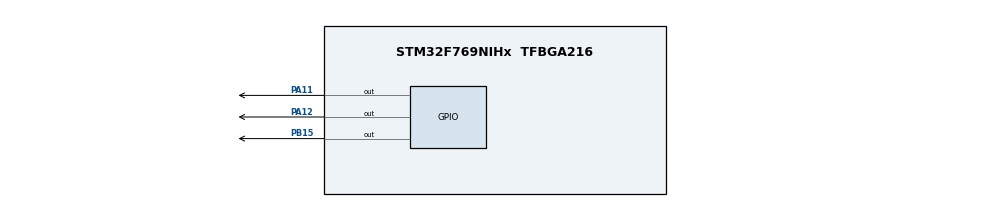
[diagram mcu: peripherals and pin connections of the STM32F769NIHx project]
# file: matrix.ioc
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Mcu.Family=STM32F7
Mcu.Name=STM32F769NIHx
Mcu.Package=TFBGA216
NVIC.PriorityGroup=NVIC_PRIORITYGROUP_4
PA11.Signal=GPIO_Output
PA12.Signal=GPIO_Output
PB15.Signal=GPIO_Output
ProjectManager.HeapSize=0x200
ProjectManager.StackSize=0x400
ProjectManager.TargetToolchain=STM32CubeIDE
RCC.HSE_VALUE=25000000
RCC.HSI_VALUE=16000000
RCC.LSE_VALUE=32768
RCC.USBFreq_Value=96000000
RCC.VCOOutputFreq_Value=192000000
board=custom

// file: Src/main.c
/* USER CODE BEGIN Header */
/**
  ******************************************************************************
  * @file           : main.c
  * @brief          : Main program body
  ******************************************************************************
  * @attention
  *
  * <h2><center>&copy; Copyright (c) 2019 STMicroelectronics.
  * All rights reserved.</center></h2>
  *
  * This software component is licensed by ST under BSD 3-Clause license,
  * the "License"; You may not use this file except in compliance with the
  * License. You may obtain a copy of the License at:
  *                        opensource.org/licenses/BSD-3-Clause
  *
  ******************************************************************************
  */
/* USER CODE END Header */

#include "main.h"

/* USER CODE BEGIN PTD */
uint8_t disp1ay[38][8]={
{0x3C,0x42,0x42,0x42,0x42,0x42,0x42,0x3C},//0
{0x10,0x30,0x50,0x10,0x10,0x10,0x10,0x7c},//1
{0x7E,0x2,0x2,0x7E,0x40,0x40,0x40,0x7E},//2
{0x3E,0x2,0x2,0x3E,0x2,0x2,0x3E,0x0},//3
{0x8,0x18,0x28,0x48,0xFE,0x8,0x8,0x8},//4
{0x3C,0x20,0x20,0x3C,0x4,0x4,0x3C,0x0},//5
{0x3C,0x20,0x20,0x3C,0x24,0x24,0x3C,0x0},//6
{0x3E,0x22,0x4,0x8,0x8,0x8,0x8,0x8},//7
{0x0,0x3E,0x22,0x22,0x3E,0x22,0x22,0x3E},//8
{0x3E,0x22,0x22,0x3E,0x2,0x2,0x2,0x3E},//9
{0x18,0x24,0x42,0x42,0x7E,0x42,0x42,0x42},//A
{0x3C,0x22,0x22,0x3c,0x22,0x22,0x3C,0x0},//B
{0x3C,0x40,0x40,0x40,0x40,0x40,0x40,0x3C},//C
{0x7C,0x22,0x22,0x22,0x22,0x22,0x22,0x7C},//D
{0x7C,0x40,0x40,0x7C,0x40,0x40,0x40,0x7C},//E
{0x7C,0x40,0x40,0x7C,0x40,0x40,0x40,0x40},//F
{0x3C,0x40,0x40,0x40,0x4c,0x44,0x44,0x3C},//G
{0x44,0x44,0x44,0x7C,0x44,0x44,0x44,0x44},//H
{0x7C,0x10,0x10,0x10,0x10,0x10,0x10,0x7C},//I
{0x3C,0x8,0x8,0x8,0x8,0x8,0x48,0x30},//J
{0x0,0x24,0x28,0x30,0x20,0x30,0x28,0x24},//K
{0x40,0x40,0x40,0x40,0x40,0x40,0x40,0x7C},//L
{0x81,0xC3,0xA5,0x99,0x81,0x81,0x81,0x81},//M
{0x0,0x42,0x62,0x52,0x4A,0x46,0x42,0x0},//N
{0x3C,0x42,0x42,0x42,0x42,0x42,0x42,0x3C},//O
{0x3C,0x22,0x22,0x22,0x3C,0x20,0x20,0x20},//P
{0x1C,0x22,0x22,0x22,0x22,0x26,0x22,0x1D},//Q
{0x3C,0x22,0x22,0x22,0x3C,0x24,0x22,0x21},//R
{0x0,0x1E,0x20,0x20,0x3E,0x2,0x2,0x3C},//S
{0x0,0x3E,0x8,0x8,0x8,0x8,0x8,0x8},//T
{0x42,0x42,0x42,0x42,0x42,0x42,0x22,0x1C},//U
{0x42,0x42,0x42,0x42,0x42,0x42,0x24,0x18},//V
{0x0,0x49,0x49,0x49,0x49,0x2A,0x1C,0x0},//W
{0x0,0x41,0x22,0x14,0x8,0x14,0x22,0x41},//X
{0x41,0x22,0x14,0x8,0x8,0x8,0x8,0x8},//Y
{0x0,0x7F,0x2,0x4,0x8,0x10,0x20,0x7F},//Z
{0x1C,0x1C,0x7F,0x5D,0x5D,0x14,0x14,0x14},//standing man
{0x38,0x38,0x7E,0x7A,0xBA,0x44,0x42,0x41},//walking man
};
/* USER CODE END PTD */

void SystemClock_Config(void);
static void MX_GPIO_Init(void);

/* USER CODE BEGIN 0 */
void write_byte(uint8_t byte)
{
	    for(int i=0;i<8;i++)
          {
	    	 HAL_GPIO_WritePin(GPIOA, GPIO_PIN_12, 0);  // Pull the CLK LOW
	    	 HAL_GPIO_WritePin(GPIOB, GPIO_PIN_15, byte&0x80);// Write one BIT data MSB first
             byte = byte<<1;  // shift the data to the left
             HAL_GPIO_WritePin(GPIOA, GPIO_PIN_12, 1);  // Pull the CLK HIGH
           }
}

void write_max (uint8_t address, uint8_t data)
{
	HAL_GPIO_WritePin(GPIOA, GPIO_PIN_11, 0);   // Pull the CS pin LOW
    write_byte(address);   //  write address
    write_byte(data);  //  write data
    HAL_GPIO_WritePin(GPIOA, GPIO_PIN_11, 1);  // pull the CS HIGH
}

void max_init(void)
{
 write_max(0x09, 0x00);       //  no decoding
 write_max(0x0a, 0x03);       //  brightness intensity
 write_max(0x0b, 0x07);       //  scan limit = 8 LEDs
 write_max(0x0c, 0x01);       //  power down =0，normal mode = 1
 write_max(0x0f, 0x00);       //  no test display
}
/* USER CODE END 0 */

int main(void)
{

  /* MCU Configuration--------------------------------------------------------*/

  /* Reset of all peripherals, Initializes the Flash interface and the Systick. */
  HAL_Init();

  /* Configure the system clock */
  SystemClock_Config();

  /* Initialize all configured peripherals */
  MX_GPIO_Init();

  /* Infinite loop */
  /* USER CODE BEGIN WHILE */
  max_init();
  while (1)
  {
    /* USER CODE END WHILE */
	  for(int i=1;i<9;i++)
	  {
		  write_max (i,disp1ay[36][i-1]);
	  }
	  HAL_Delay (300);
	  for(int i=1;i<9;i++)
	  {
		  write_max (i,disp1ay[37][i-1]);
	  }
	  HAL_Delay (300);
  }
}

void SystemClock_Config(void)
{
  RCC_OscInitTypeDef RCC_OscInitStruct = {0};
  RCC_ClkInitTypeDef RCC_ClkInitStruct = {0};

  /** Configure the main internal regulator output voltage
  */
  __HAL_RCC_PWR_CLK_ENABLE();
  __HAL_PWR_VOLTAGESCALING_CONFIG(PWR_REGULATOR_VOLTAGE_SCALE3);
  /** Initializes the CPU, AHB and APB busses clocks
  */
  RCC_OscInitStruct.OscillatorType = RCC_OSCILLATORTYPE_HSI;
  RCC_OscInitStruct.HSIState = RCC_HSI_ON;
  RCC_OscInitStruct.HSICalibrationValue = RCC_HSICALIBRATION_DEFAULT;
  RCC_OscInitStruct.PLL.PLLState = RCC_PLL_NONE;
  if (HAL_RCC_OscConfig(&RCC_OscInitStruct) != HAL_OK)
  {
    Error_Handler();
  }
  /** Initializes the CPU, AHB and APB busses clocks
  */
  RCC_ClkInitStruct.ClockType = RCC_CLOCKTYPE_HCLK|RCC_CLOCKTYPE_SYSCLK
                              |RCC_CLOCKTYPE_PCLK1|RCC_CLOCKTYPE_PCLK2;
  RCC_ClkInitStruct.SYSCLKSource = RCC_SYSCLKSOURCE_HSI;
  RCC_ClkInitStruct.AHBCLKDivider = RCC_SYSCLK_DIV1;
  RCC_ClkInitStruct.APB1CLKDivider = RCC_HCLK_DIV1;
  RCC_ClkInitStruct.APB2CLKDivider = RCC_HCLK_DIV1;

  if (HAL_RCC_ClockConfig(&RCC_ClkInitStruct, FLASH_LATENCY_0) != HAL_OK)
  {
    Error_Handler();
  }
}

static void MX_GPIO_Init(void)
{
  GPIO_InitTypeDef GPIO_InitStruct = {0};

  /* GPIO Ports Clock Enable */
  __HAL_RCC_GPIOA_CLK_ENABLE();
  __HAL_RCC_GPIOB_CLK_ENABLE();

  /*Configure GPIO pin Output Level */
  HAL_GPIO_WritePin(GPIOA, GPIO_PIN_12|GPIO_PIN_11, GPIO_PIN_RESET);

  /*Configure GPIO pin Output Level */
  HAL_GPIO_WritePin(GPIOB, GPIO_PIN_15, GPIO_PIN_RESET);

  /*Configure GPIO pins : PA12 PA11 */
  GPIO_InitStruct.Pin = GPIO_PIN_12|GPIO_PIN_11;
  GPIO_InitStruct.Mode = GPIO_MODE_OUTPUT_PP;
  GPIO_InitStruct.Pull = GPIO_NOPULL;
  GPIO_InitStruct.Speed = GPIO_SPEED_FREQ_LOW;
  HAL_GPIO_Init(GPIOA, &GPIO_InitStruct);

  /*Configure GPIO pin : PB15 */
  GPIO_InitStruct.Pin = GPIO_PIN_15;
  GPIO_InitStruct.Mode = GPIO_MODE_OUTPUT_PP;
  GPIO_InitStruct.Pull = GPIO_NOPULL;
  GPIO_InitStruct.Speed = GPIO_SPEED_FREQ_LOW;
  HAL_GPIO_Init(GPIOB, &GPIO_InitStruct);

}

void Error_Handler(void)
{
}

/************************ (C) COPYRIGHT STMicroelectronics *****END OF FILE****/
